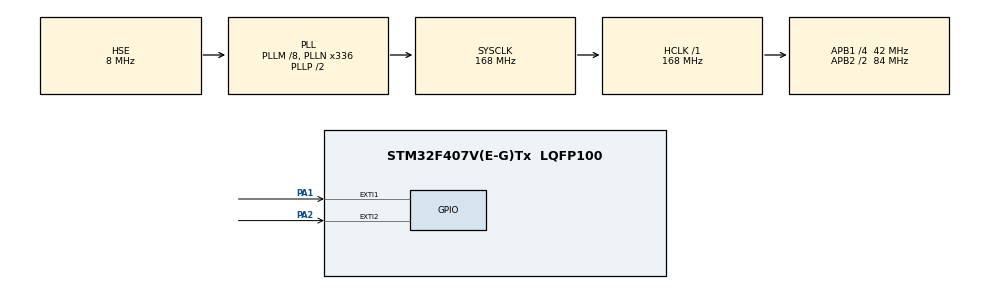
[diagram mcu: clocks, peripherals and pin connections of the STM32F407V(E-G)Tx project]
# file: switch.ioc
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Mcu.Family=STM32F4
Mcu.Name=STM32F407V(E-G)Tx
Mcu.Package=LQFP100
NVIC.EXTI1_IRQn=true\:0\:0\:false\:false\:true\:true\:true\:true
NVIC.EXTI2_IRQn=true\:0\:0\:false\:false\:true\:true\:true\:true
NVIC.PriorityGroup=NVIC_PRIORITYGROUP_0
NVIC.TIM2_IRQn=true\:0\:0\:false\:false\:true\:true\:true\:true
PA1.Signal=GPXTI1
PA13.Mode=Serial_Wire
PA13.Signal=SYS_JTMS-SWDIO
PA14.Mode=Serial_Wire
PA14.Signal=SYS_JTCK-SWCLK
PA2.Signal=GPXTI2
PH0-OSC_IN.Mode=HSE-External-Oscillator
PH0-OSC_IN.Signal=RCC_OSC_IN
PH1-OSC_OUT.Mode=HSE-External-Oscillator
PH1-OSC_OUT.Signal=RCC_OSC_OUT
ProjectManager.HeapSize=0x200
ProjectManager.StackSize=0x400
ProjectManager.TargetToolchain=STM32CubeIDE
RCC.48MHZClocksFreq_Value=48000000
RCC.AHBFreq_Value=168000000
RCC.APB1CLKDivider=RCC_HCLK_DIV4
RCC.APB1Freq_Value=42000000
RCC.APB1TimFreq_Value=84000000
RCC.APB2CLKDivider=RCC_HCLK_DIV2
RCC.APB2Freq_Value=84000000
RCC.APB2TimFreq_Value=168000000
RCC.CortexFreq_Value=168000000
RCC.HCLKFreq_Value=168000000
RCC.HSE_VALUE=8000000
RCC.HSI_VALUE=16000000
RCC.LSE_VALUE=32768
RCC.PLLM=8
RCC.PLLN=336
RCC.PLLQ=7
RCC.PLLSourceVirtual=RCC_PLLSOURCE_HSE
RCC.SYSCLKFreq_VALUE=168000000
RCC.SYSCLKSource=RCC_SYSCLKSOURCE_PLLCLK
RCC.VCOOutputFreq_Value=336000000
TIM2.Period=1000-1
TIM2.Prescaler=168-1
VP_TIM2_VS_ClockSourceINT.Mode=Internal
board=STM32F407G-DISC1

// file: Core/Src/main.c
/* USER CODE BEGIN Header */
/**
  ******************************************************************************
  * @file           : main.c
  * @brief          : Main program body
  ******************************************************************************
  * @attention
  *
  * Copyright (c) 2025 STMicroelectronics.
  * All rights reserved.
  *
  * This software is licensed under terms that can be found in the LICENSE file
  * in the root directory of this software component.
  * If no LICENSE file comes with this software, it is provided AS-IS.
  *
  ******************************************************************************
  */
/* USER CODE END Header */
#include "main.h"

/* USER CODE BEGIN Includes */

#include <stdbool.h>
#include<stdio.h>
/* USER CODE END Includes */

TIM_HandleTypeDef htim2;

void SystemClock_Config(void);
static void MX_GPIO_Init(void);
static void MX_TIM2_Init(void);

/* USER CODE BEGIN 0 */

bool normal_mode = true;  // flag to notify the normal mode
bool calibration_mode = false; // flag to notify the calibration mode

bool b1_pressed = false;
bool b2_pressed = false;
volatile uint32_t b1_Duration =0; // variable to check the millisecond using timer2
volatile uint32_t longpress = 0;

volatile uint8_t count = 0;
bool hour = 0; // flag for setting hour
bool min = 0; // flag for setting minutes

volatile uint8_t hr = 0;  // to store the hours
volatile uint8_t minutes = 0; // to store minutes

volatile uint32_t previousMillis = 0; // Variable to store the last tick

void B1_Press(void);
void B2_Press(void);
void CalibrationMode(void);
void reset(void);

void printTime(void)
{
	// time : 5 : 19 PM

	printf("Time : %02d : %02d PM",hr,minutes);
}

/* USER CODE END 0 */

int main(void)
{

  /* MCU Configuration--------------------------------------------------------*/

  /* Reset of all peripherals, Initializes the Flash interface and the Systick. */
  HAL_Init();

  /* Configure the system clock */
  SystemClock_Config();

  /* Initialize all configured peripherals */
  MX_GPIO_Init();
  MX_TIM2_Init();
  /* USER CODE BEGIN 2 */

  HAL_TIM_Base_Start_IT(&htim2);

  /* USER CODE END 2 */

  /* Infinite loop */
  while (1)
  {

    /* USER CODE BEGIN 3 */

	  // Main loop

	  // Get the current tick
	         uint32_t currentMillis = HAL_GetTick();

	         // Check if 2 seconds (2000 ms) have passed
	         if (currentMillis - previousMillis >= 2000)
	         {
	             previousMillis = currentMillis; // Update the previous tick
	             printTime(); // Call the function to print the time[ Time : 05:19 PM ]
	         }
	         //show the time for every two seconds.....

	          if (HAL_GPIO_ReadPin(GPIOA, GPIO_PIN_1) == GPIO_PIN_RESET)
	          {
	              b1_pressed = false; // Reset flag when button is released
	          }
	          if (HAL_GPIO_ReadPin(GPIOA, GPIO_PIN_2) == GPIO_PIN_RESET)
	          {
	              b2_pressed = false; // Reset flag when button is released
	          }

  }
  /* USER CODE END 3 */
}

void SystemClock_Config(void)
{
  RCC_OscInitTypeDef RCC_OscInitStruct = {0};
  RCC_ClkInitTypeDef RCC_ClkInitStruct = {0};

  /** Configure the main internal regulator output voltage
  */
  __HAL_RCC_PWR_CLK_ENABLE();
  __HAL_PWR_VOLTAGESCALING_CONFIG(PWR_REGULATOR_VOLTAGE_SCALE1);

  /** Initializes the RCC Oscillators according to the specified parameters
  * in the RCC_OscInitTypeDef structure.
  */
  RCC_OscInitStruct.OscillatorType = RCC_OSCILLATORTYPE_HSE;
  RCC_OscInitStruct.HSEState = RCC_HSE_ON;
  RCC_OscInitStruct.PLL.PLLState = RCC_PLL_ON;
  RCC_OscInitStruct.PLL.PLLSource = RCC_PLLSOURCE_HSE;
  RCC_OscInitStruct.PLL.PLLM = 8;
  RCC_OscInitStruct.PLL.PLLN = 336;
  RCC_OscInitStruct.PLL.PLLP = RCC_PLLP_DIV2;
  RCC_OscInitStruct.PLL.PLLQ = 7;
  if (HAL_RCC_OscConfig(&RCC_OscInitStruct) != HAL_OK)
  {
    Error_Handler();
  }

  /** Initializes the CPU, AHB and APB buses clocks
  */
  RCC_ClkInitStruct.ClockType = RCC_CLOCKTYPE_HCLK|RCC_CLOCKTYPE_SYSCLK
                              |RCC_CLOCKTYPE_PCLK1|RCC_CLOCKTYPE_PCLK2;
  RCC_ClkInitStruct.SYSCLKSource = RCC_SYSCLKSOURCE_PLLCLK;
  RCC_ClkInitStruct.AHBCLKDivider = RCC_SYSCLK_DIV1;
  RCC_ClkInitStruct.APB1CLKDivider = RCC_HCLK_DIV4;
  RCC_ClkInitStruct.APB2CLKDivider = RCC_HCLK_DIV2;

  if (HAL_RCC_ClockConfig(&RCC_ClkInitStruct, FLASH_LATENCY_5) != HAL_OK)
  {
    Error_Handler();
  }
}

static void MX_TIM2_Init(void)
{

  TIM_ClockConfigTypeDef sClockSourceConfig = {0};
  TIM_MasterConfigTypeDef sMasterConfig = {0};

  htim2.Instance = TIM2;
  htim2.Init.Prescaler = 168-1;
  htim2.Init.CounterMode = TIM_COUNTERMODE_UP;
  htim2.Init.Period = 1000-1;
  htim2.Init.ClockDivision = TIM_CLOCKDIVISION_DIV1;
  htim2.Init.AutoReloadPreload = TIM_AUTORELOAD_PRELOAD_DISABLE;
  if (HAL_TIM_Base_Init(&htim2) != HAL_OK)
  {
    Error_Handler();
  }
  sClockSourceConfig.ClockSource = TIM_CLOCKSOURCE_INTERNAL;
  if (HAL_TIM_ConfigClockSource(&htim2, &sClockSourceConfig) != HAL_OK)
  {
    Error_Handler();
  }
  sMasterConfig.MasterOutputTrigger = TIM_TRGO_RESET;
  sMasterConfig.MasterSlaveMode = TIM_MASTERSLAVEMODE_DISABLE;
  if (HAL_TIMEx_MasterConfigSynchronization(&htim2, &sMasterConfig) != HAL_OK)
  {
    Error_Handler();
  }

}

static void MX_GPIO_Init(void)
{
  GPIO_InitTypeDef GPIO_InitStruct = {0};

  /* GPIO Ports Clock Enable */
  __HAL_RCC_GPIOH_CLK_ENABLE();
  __HAL_RCC_GPIOA_CLK_ENABLE();

  /*Configure GPIO pins : PA1 PA2 */
  GPIO_InitStruct.Pin = GPIO_PIN_1|GPIO_PIN_2;
  GPIO_InitStruct.Mode = GPIO_MODE_IT_RISING;
  GPIO_InitStruct.Pull = GPIO_NOPULL;
  HAL_GPIO_Init(GPIOA, &GPIO_InitStruct);

  /* EXTI interrupt init*/
  HAL_NVIC_SetPriority(EXTI1_IRQn, 0, 0);
  HAL_NVIC_EnableIRQ(EXTI1_IRQn);

  HAL_NVIC_SetPriority(EXTI2_IRQn, 0, 0);
  HAL_NVIC_EnableIRQ(EXTI2_IRQn);

}

/* USER CODE BEGIN 4 */

void HAL_GPIO_EXTI_Callback(uint16_t GPIO_Pin)
{
    if (GPIO_Pin == GPIO_PIN_1) // Button 1 triggered the interrupt
    {

        if (HAL_GPIO_ReadPin(GPIOA, GPIO_PIN_1) == GPIO_PIN_SET)
        {
           b1_pressed = true;

        }
    }
    else if (GPIO_Pin == GPIO_PIN_2) // Button 2 triggered the interrupt
    {
        if (HAL_GPIO_ReadPin(GPIOA, GPIO_PIN_2) == GPIO_PIN_SET)
        {
           b2_pressed = true;
           if(hour)
           {
            hr++; // for each press hour will increase
            if(hr>24)
            	{
            	hr = 0;
            	}
           }
           if(min)
           {

        	   minutes++; // for each press minutes will increase
        	   if(minutes>60)
        	   {
        		   minutes=0;
        	   }
           }
           printTime(); // printing the time...

        }
    }
}

void HAL_TIM_PeriodElapsedCallback(TIM_HandleTypeDef *htim)
{
	if ( htim->Instance == TIM2)
		{
		if(b1_pressed)
		{
			b1_Duration++;

			if(b1_Duration == 500 && calibration_mode) // short press of detecting 0.5 second
			{
				count ++;
			}

			if(b1_Duration == 3000) // long press of detecting 3 second
			{
				count = 0;
				calibration_mode = !calibration_mode;

				if(calibration_mode)
				{
					printf("enter calibration mode\n");
					normal_mode = false;
				}
				else
				{
					hour = false;
					min = false;
					printf("exit calibration mode\n");
					normal_mode = true;
					printf("....normal mode....\n");

				}

			}
		}
		else
		{
			b1_Duration = 0;
			if(count > 2)
			{
				count = 0;

			}
		}
		if(b2_pressed )
		{
			if(count == 1 && calibration_mode)//in first short press we can set the hours
			{
				hour = true;
			}
			else
			{
				hour = false;
			}
			if(count == 2 && calibration_mode)
			{
				min = true; // in Second short press we can set the minutes
				hour = false;
			}
			else
			{
				min = false;
			}
		}

	}
}

/* USER CODE END 4 */

void Error_Handler(void)
{
  __disable_irq();
  while (1)
  {
  }
}
